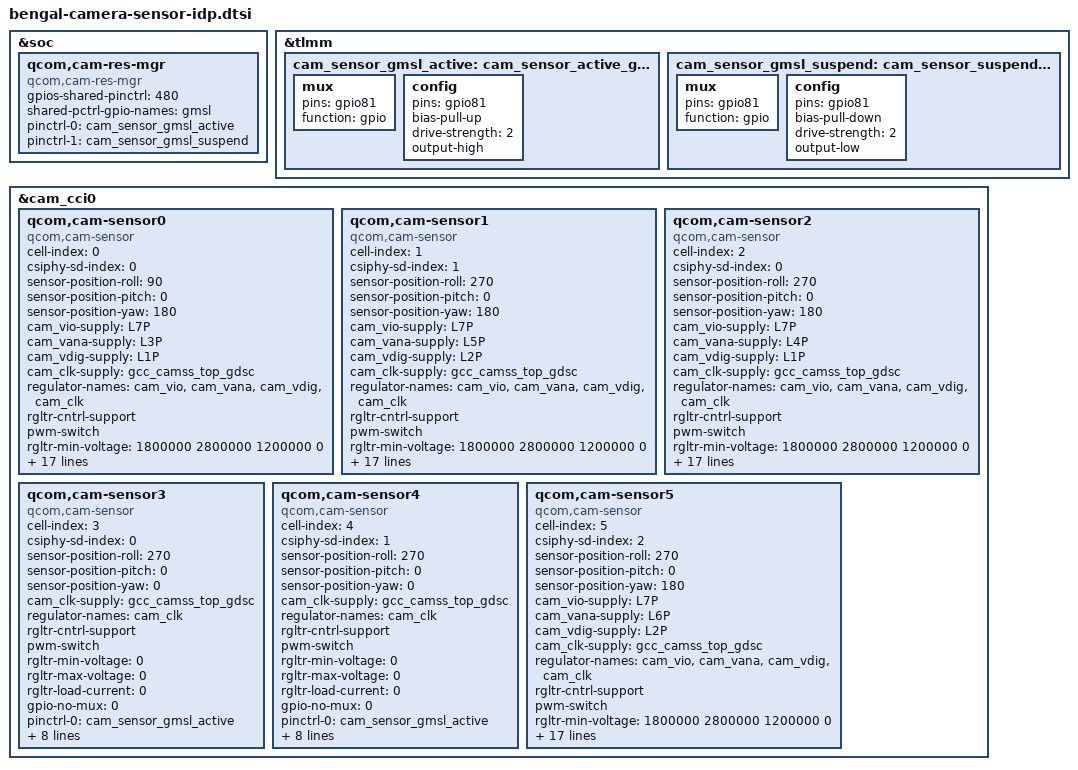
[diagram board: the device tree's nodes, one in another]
#include <dt-bindings/clock/qcom,gcc-bengal.h>
&soc {
	qcom,cam-res-mgr {
		compatible = "qcom,cam-res-mgr";
		status = "ok";
		gpios-shared-pinctrl = <480>;
		shared-pctrl-gpio-names = "gmsl";
		pinctrl-names = "gmsl_active", "gmsl_suspend";
		pinctrl-0 = <&cam_sensor_gmsl_active>;
		pinctrl-1 = <&cam_sensor_gmsl_suspend>;
	};
};

&tlmm {
	cam_sensor_gmsl_active: cam_sensor_active_gmsl {
		/* RESET */
		mux {
			pins = "gpio81";
			function = "gpio";
		};

		config {
			pins = "gpio81";
			bias-pull-up;
			drive-strength = <2>; /* 2 MA */
			output-high;
		};
	};

	cam_sensor_gmsl_suspend: cam_sensor_suspend_gmsl {
		/* RESET */
		mux {
			pins = "gpio81";
			function = "gpio";
		};

		config {
			pins = "gpio81";
			bias-pull-down; /* PULL DOWN */
			drive-strength = <2>; /* 2 MA */
			output-low;
		};
	};
};

&cam_cci0 {

	/* CAM0A */
	qcom,cam-sensor0 {
		cell-index = <0>;
		compatible = "qcom,cam-sensor";
		csiphy-sd-index = <0>;
		sensor-position-roll = <90>;
		sensor-position-pitch = <0>;
		sensor-position-yaw = <180>;
		cam_vio-supply = <&L7P>;
		cam_vana-supply = <&L3P>;
		cam_vdig-supply = <&L1P>;

		cam_clk-supply = <&gcc_camss_top_gdsc>;
		regulator-names = "cam_vio", "cam_vana", "cam_vdig",
			"cam_clk";
		rgltr-cntrl-support;
		pwm-switch;
		rgltr-min-voltage = <1800000 2800000 1200000 0>;
		rgltr-max-voltage = <1800000 2800000 1200000 0>;
		rgltr-load-current = <120000 80000 1200000 0>;
		gpio-no-mux = <0>;
		pinctrl-names = "cam_default", "cam_suspend";
		pinctrl-0 = <&cam_sensor_mclk3_active
				&cam_sensor_active_rst0>;
		pinctrl-1 = <&cam_sensor_mclk3_suspend
				&cam_sensor_suspend_rst0>;
		gpios = <&tlmm 28 0>,
			<&tlmm 18 0>;
		gpio-reset = <1>;
		gpio-req-tbl-num = <0 1>;
		gpio-req-tbl-flags = <1 0>;
		gpio-req-tbl-label = "CAMIF_MCLK3",
					"CAM_RESET0";
		sensor-mode = <0>;
		cci-master = <1>;
		status = "ok";
		clocks = <&gcc GCC_CAMSS_MCLK3_CLK>;
		clock-names = "cam_clk";
		clock-cntl-level = "turbo";
		clock-rates = <24000000>;
	};

	/* CAM1 */
	qcom,cam-sensor1 {
		cell-index = <1>;
		compatible = "qcom,cam-sensor";
		csiphy-sd-index = <1>;
		sensor-position-roll = <270>;
		sensor-position-pitch = <0>;
		sensor-position-yaw = <180>;
		cam_vio-supply = <&L7P>;
		cam_vana-supply = <&L5P>;
		cam_vdig-supply = <&L2P>;

		cam_clk-supply = <&gcc_camss_top_gdsc>;
		regulator-names = "cam_vio", "cam_vana", "cam_vdig",
			"cam_clk";
		rgltr-cntrl-support;
		pwm-switch;
		rgltr-min-voltage = <1800000 2800000 1200000 0>;
		rgltr-max-voltage = <1800000 2800000 1200000 0>;
		rgltr-load-current = <120000 80000 1200000 0>;
		gpio-no-mux = <0>;
		pinctrl-names = "cam_default", "cam_suspend";
		pinctrl-0 = <&cam_sensor_mclk1_active
				&cam_sensor_active_rst1>;
		pinctrl-1 = <&cam_sensor_mclk1_suspend
				&cam_sensor_suspend_rst1>;
		gpios = <&tlmm 21 0>,
				<&tlmm 24 0>;
		gpio-reset = <1>;
		gpio-req-tbl-num = <0 1>;
		gpio-req-tbl-flags = <1 0>;
		gpio-req-tbl-label = "CAMIF_MCLK1",
					"CAM_RESET1";
		sensor-mode = <0>;
		cci-master = <0>;
		status = "ok";
		clocks = <&gcc GCC_CAMSS_MCLK1_CLK>;
		clock-names = "cam_clk";
		clock-cntl-level = "turbo";
		clock-rates = <24000000>;
	};

	/* CAM0B */
	qcom,cam-sensor2 {
		cell-index = <2>;
		compatible = "qcom,cam-sensor";
		csiphy-sd-index = <0>;
		sensor-position-roll = <270>;
		sensor-position-pitch = <0>;
		sensor-position-yaw = <180>;
		cam_vio-supply = <&L7P>;
		cam_vana-supply = <&L4P>;
		cam_vdig-supply = <&L1P>;

		cam_clk-supply = <&gcc_camss_top_gdsc>;
		regulator-names = "cam_vio", "cam_vana", "cam_vdig",
			"cam_clk";
		rgltr-cntrl-support;
		pwm-switch;
		rgltr-min-voltage = <1800000 2800000 1200000 0>;
		rgltr-max-voltage = <1800000 2800000 1200000 0>;
		rgltr-load-current = <120000 80000 1200000 0>;
		gpio-no-mux = <0>;
		pinctrl-names = "cam_default", "cam_suspend";
		pinctrl-0 = <&cam_sensor_mclk0_active
				&cam_sensor_active_rst2>;
		pinctrl-1 = <&cam_sensor_mclk0_suspend
				&cam_sensor_suspend_rst2>;
		gpios = <&tlmm 20 0>,
				<&tlmm 44 0>;
		gpio-reset = <1>;
		gpio-req-tbl-num = <0 1>;
		gpio-req-tbl-flags = <1 0>;
		gpio-req-tbl-label = "CAMIF_MCLK0",
					"CAM_RESET0";
		sensor-mode = <0>;
		cci-master = <0>;
		status = "ok";
		clocks = <&gcc GCC_CAMSS_MCLK0_CLK>;
		clock-names = "cam_clk";
		clock-cntl-level = "turbo";
		clock-rates = <24000000>;
	};

		/* GMSL-1 */
	qcom,cam-sensor3 {
		cell-index = <3>;
		compatible = "qcom,cam-sensor";
		csiphy-sd-index = <0>;
		sensor-position-roll = <270>;
		sensor-position-pitch = <0>;
		sensor-position-yaw = <0>;
		cam_clk-supply = <&gcc_camss_top_gdsc>;
		regulator-names = "cam_clk";
		rgltr-cntrl-support;
		pwm-switch;
		rgltr-min-voltage  = <0>;
		rgltr-max-voltage  = <0>;
		rgltr-load-current = <0>;
		gpio-no-mux = <0>;
		pinctrl-names = "cam_default", "cam_suspend";
		pinctrl-0 = <&cam_sensor_gmsl_active>;
		pinctrl-1 = <&cam_sensor_gmsl_suspend>;
		gpios = <&tlmm 81 0>;
		gpio-reset = <0>;
		gpio-req-tbl-num = <0>;
		gpio-req-tbl-flags = <0>;
		gpio-req-tbl-label = "CAM_RESET2";
		sensor-mode = <0>;
		cci-master = <0>;
		status = "ok";
	};

	/* GMSL-2 */
	qcom,cam-sensor4 {
		cell-index = <4>;
		compatible = "qcom,cam-sensor";
		csiphy-sd-index = <1>;
		sensor-position-roll = <270>;
		sensor-position-pitch = <0>;
		sensor-position-yaw = <0>;
		cam_clk-supply = <&gcc_camss_top_gdsc>;
		regulator-names = "cam_clk";
		rgltr-cntrl-support;
		pwm-switch;
		rgltr-min-voltage  = <0>;
		rgltr-max-voltage  = <0>;
		rgltr-load-current = <0>;
		gpio-no-mux = <0>;
		pinctrl-names = "cam_default", "cam_suspend";
		pinctrl-0 = <&cam_sensor_gmsl_active>;
		pinctrl-1 = <&cam_sensor_gmsl_suspend>;
		gpios = <&tlmm 81 0>;
		gpio-reset = <0>;
		gpio-req-tbl-num = <0>;
		gpio-req-tbl-flags = <0>;
		gpio-req-tbl-label = "CAM_RESET2";
		sensor-mode = <0>;
		cci-master = <0>;
		status = "ok";
	};

	/* CAM2 */
	qcom,cam-sensor5 {
		cell-index = <5>;
		compatible = "qcom,cam-sensor";
		csiphy-sd-index = <2>;
		sensor-position-roll = <270>;
		sensor-position-pitch = <0>;
		sensor-position-yaw = <180>;
		cam_vio-supply = <&L7P>;
		cam_vana-supply = <&L6P>;
		cam_vdig-supply = <&L2P>;

		cam_clk-supply = <&gcc_camss_top_gdsc>;
		regulator-names = "cam_vio", "cam_vana", "cam_vdig",
			"cam_clk";
		rgltr-cntrl-support;
		pwm-switch;
		rgltr-min-voltage = <1800000 2800000 1200000 0>;
		rgltr-max-voltage = <1800000 2800000 1200000 0>;
		rgltr-load-current = <120000 80000 1200000 0>;
		gpio-no-mux = <0>;
		pinctrl-names = "cam_default", "cam_suspend";
		pinctrl-0 = <&cam_sensor_mclk2_active
				&cam_sensor_active_rst5>;
		pinctrl-1 = <&cam_sensor_mclk2_suspend
				&cam_sensor_suspend_rst5>;
		gpios = <&tlmm 27 0>,
				<&tlmm 19 0>;
		gpio-reset = <1>;
		gpio-req-tbl-num = <0 1>;
		gpio-req-tbl-flags = <1 0>;
		gpio-req-tbl-label = "CAMIF_MCLK2",
					"CAM_RESET2";
		sensor-mode = <0>;
		cci-master = <1>;
		status = "ok";
		clocks = <&gcc GCC_CAMSS_MCLK2_CLK>;
		clock-names = "cam_clk";
		clock-cntl-level = "turbo";
		clock-rates = <24000000>;
	};
};
